# STM32H5E4xx register map
File version: 1.0
Registers are 32-bit, read-write, reset 0x0 unless marked. A register's access mark holds for its fields unless they carry their own. Offsets are from the block's base; [hi:lo] are bit positions; lines under a group give offsets from that group; {n}, {i} and the like mark numbered series.

## ADC1 — ADC
Base 0x42028000
Same registers: ADC2 0x42028100, ADC1_S 0x52028000, ADC2_S 0x52028100
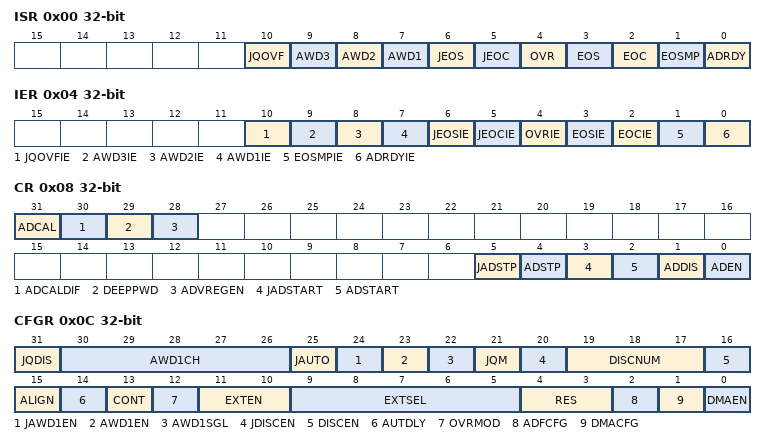
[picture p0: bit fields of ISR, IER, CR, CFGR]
0x00 ISR — ADC interrupt and status register
  [10] JQOVF — ADC group injected contexts queue overflow flag
  [9] AWD3 — ADC analog watchdog 3 flag
  [8] AWD2 — ADC analog watchdog 2 flag
  [7] AWD1 — ADC analog watchdog 1 flag
  [6] JEOS — ADC group injected end of sequence conversions flag
  [5] JEOC — ADC group injected end of unitary conversion flag
  [4] OVR — ADC group regular overrun flag
  [3] EOS — ADC group regular end of sequence conversions flag
  [2] EOC — ADC group regular end of unitary conversion flag
  [1] EOSMP — ADC group regular end of sampling flag
  [0] ADRDY — ADC ready flag
0x04 IER — ADC interrupt enable register
  [10] JQOVFIE — ADC group injected contexts queue overflow interrupt
  [9] AWD3IE — ADC analog watchdog 3 interrupt
  [8] AWD2IE — ADC analog watchdog 2 interrupt
  [7] AWD1IE — ADC analog watchdog 1 interrupt
  [6] JEOSIE — ADC group injected end of sequence conversions interrupt
  [5] JEOCIE — ADC group injected end of unitary conversion interrupt
  [4] OVRIE — ADC group regular overrun interrupt
  [3] EOSIE — ADC group regular end of sequence conversions interrupt
  [2] EOCIE — ADC group regular end of unitary conversion interrupt
  [1] EOSMPIE — ADC group regular end of sampling interrupt
  [0] ADRDYIE — ADC ready interrupt
0x08 CR — ADC control register
  [31] ADCAL — ADC calibration
  [30] ADCALDIF — ADC differential mode for calibration
  [29] DEEPPWD — ADC deep power down enable
  [28] ADVREGEN — ADC voltage regulator enable
  [5] JADSTP — ADC group injected conversion stop
  [4] ADSTP — ADC group regular conversion stop
  [3] JADSTART — ADC group injected conversion start
  [2] ADSTART — ADC group regular conversion start
  [1] ADDIS — ADC disable
  [0] ADEN — ADC enable
0x0C CFGR — ADC configuration register 1
  [31] JQDIS — ADC group injected contexts queue disable
  [30:26] AWD1CH — ADC analog watchdog 1 monitored channel selection
  [25] JAUTO — ADC group injected automatic trigger mode
    0=INDEPENDENT; 1=FROM_GRP_REGULAR
  [24] JAWD1EN — ADC analog watchdog 1 enable on scope ADC group injected
  [23] AWD1EN — ADC analog watchdog 1 enable on scope ADC group regular
  [22] AWD1SGL — ADC analog watchdog 1 monitoring a single channel or all channels
  [21] JQM — ADC group injected contexts queue mode
  [20] JDISCEN — ADC group injected sequencer discontinuous mode
    0=DISABLE; 1=DISCONT_1RANK
  [19:17] DISCNUM — ADC group regular sequencer discontinuous number of ranks
  [16] DISCEN — ADC group regular sequencer discontinuous mode
  [15] ALIGN — ADC data alignment
    0=RIGHT; 1=LEFT
  [14] AUTDLY — ADC low power auto wait
    0=MODE_NONE (No ADC low power mode activated); 1=AUTOWAIT
  [13] CONT — ADC group regular continuous conversion mode
    0=SINGLE; 1=CONTINUOUS
  [12] OVRMOD — ADC group regular overrun configuration
    0=PRESERVED; 1=OVERWRITTEN
  [11:10] EXTEN — ADC group regular external trigger polarity
    1=RISING; 2=FALLING; 3=RISINGFALLING
  [9:5] EXTSEL — ADC group regular external trigger source
  [4:3] RES — ADC data resolution
    0=RESOLUTION_12B (ADC resolution 12 bits); 1=RESOLUTION_10B (ADC resolution 10 bits); 2=RESOLUTION_8B (ADC resolution 8 bits); 3=RESOLUTION_6B (ADC resolution 6 bits)
  [2] ADFCFG — ADC ADF mode configuration
    0=NONE; 1=ENABLE
  [1] DMACFG — ADC DMA transfer configuration
  [0] DMAEN — ADC DMA transfer enable
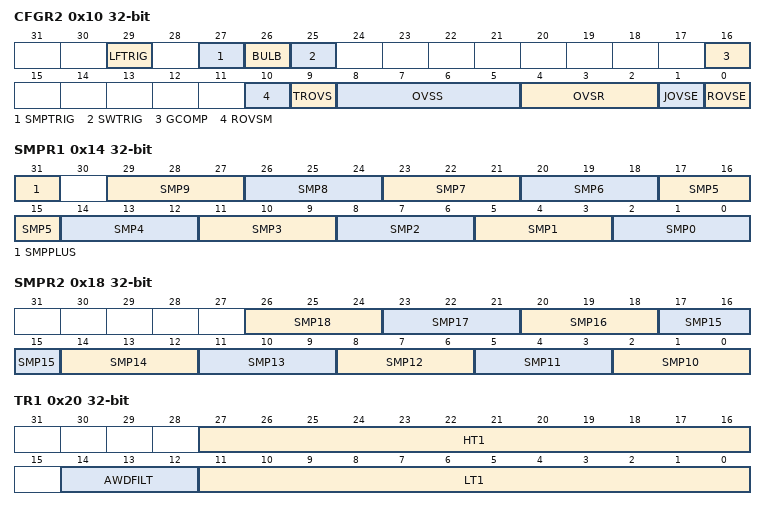
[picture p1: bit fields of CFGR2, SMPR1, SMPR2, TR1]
0x10 CFGR2 — ADC configuration register 2
  [29] LFTRIG — ADC Low Frequency Trigger
  [27] SMPTRIG — ADC Sample Time Control Trigger mode
  [26] BULB — ADC Bulb sampling mode
  [25] SWTRIG — ADC Software Trigger Bit for Sample time control trigger mode
  [16] GCOMP — ADC Gain Compensation mode
  [10] ROVSM — ADC oversampling mode managing interlaced conversions of ADC group regular and group injected
  [9] TROVS — ADC oversampling discontinuous mode (triggered mode) for ADC group regular
    0=CONT; 1=DISCONT
  [8:5] OVSS — ADC oversampling shift
    0=NONE; {v}=RIGHT_{v} (v=1..8)
  [4:2] OVSR — ADC oversampling ratio
    0=RATIO_2; 1=RATIO_4; 2=RATIO_8; 3=RATIO_16; 4=RATIO_32; 5=RATIO_64; 6=RATIO_128; 7=RATIO_256
  [1] JOVSE — ADC oversampler enable on scope ADC group injected
  [0] ROVSE — ADC oversampler enable on scope ADC group regular
0x14 SMPR1 — ADC sampling time register 1
  [31] SMPPLUS — ADC channels sampling time additional setting
    0=DEFAULT (ADC sampling time let to default settings.); 1=COMMON_3C5_REPL_2C5
  [3n+2:3n] SMP{n} (n=0..9) — ADC channel {n} sampling time selection
0x18 SMPR2 — ADC sampling time register 2
  [3n-28:3n-30] SMP{n} (n=10..18) — ADC channel {n} sampling time selection
0x20 TR1 — ADC analog watchdog 1 threshold register
  [27:16] HT1 — ADC analog watchdog 1 threshold high
  [14:12] AWDFILT — ADC analog watchdog filtering parameter
  [11:0] LT1 — ADC analog watchdog 1 threshold low
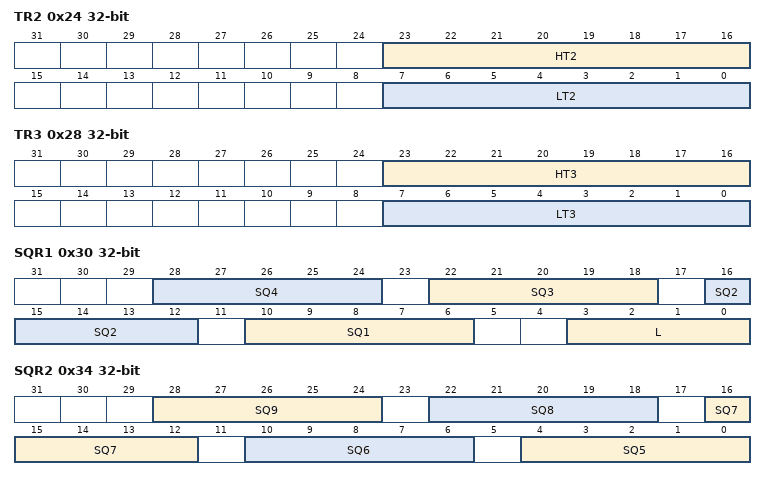
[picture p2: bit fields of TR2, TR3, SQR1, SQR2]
0x24 TR2 — ADC analog watchdog 2 threshold register
  [23:16] HT2 — ADC analog watchdog 2 threshold high
  [7:0] LT2 — ADC analog watchdog 2 threshold low
0x28 TR3 — ADC analog watchdog 3 threshold register
  [23:16] HT3 — ADC analog watchdog 3 threshold high
  [7:0] LT3 — ADC analog watchdog 3 threshold low
0x30 SQR1 — ADC group regular sequencer register 1
  [6n+4:6n] SQ{n} (n=1..4) — ADC group regular sequencer rank {n}
  [3:0] L — ADC group regular sequencer scan length
    0=DISABLE; {v}=ENABLE_{v+1}RANKS (v=1..15)
0x34 SQR2 — ADC group regular sequencer register 2
  [6n-26:6n-30] SQ{n} (n=5..9) — ADC group regular sequencer rank {n}
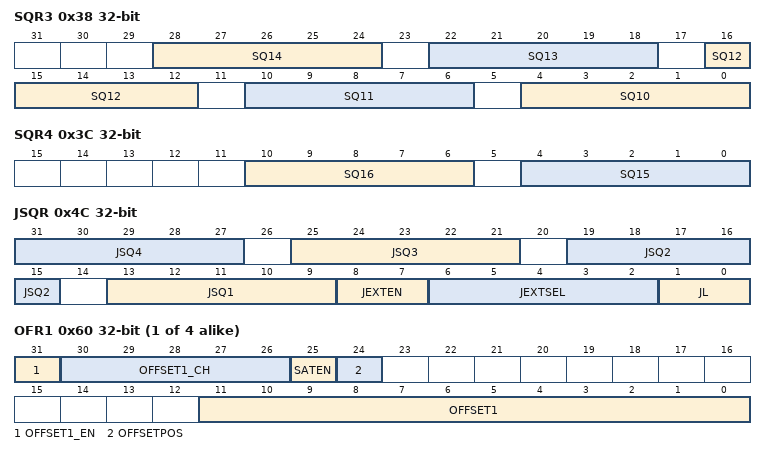
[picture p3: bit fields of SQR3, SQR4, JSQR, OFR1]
0x38 SQR3 — ADC group regular sequencer register 3
  [6n-56:6n-60] SQ{n} (n=10..14) — ADC group regular sequencer rank {n}
0x3C SQR4 — ADC group regular sequencer register 4
  [10:6] SQ16 — ADC group regular sequencer rank 16
  [4:0] SQ15 — ADC group regular sequencer rank 15
0x40 DR — ADC group regular data register
  [15:0] RDATA — ADC group regular conversion data
0x4C JSQR — ADC group injected sequencer register
  [6n+7:6n+3] JSQ{n} (n=1..4) — ADC group injected sequencer rank {n}
  [8:7] JEXTEN — ADC group injected external trigger polarity
    1=RISING; 2=FALLING; 3=RISINGFALLING
  [6:2] JEXTSEL — ADC group injected external trigger source
  [1:0] JL — ADC group injected sequencer scan length
    0=DISABLE; 1=ENABLE_2RANKS; 2=ENABLE_3RANKS; 3=ENABLE_4RANKS
{0x5C+4i} OFR{i} (i=1..4) — ADC
  [31] OFFSET{i}_EN — ADC offset number {i} enable
  [30:26] OFFSET{i}_CH — ADC offset number {i} channel selection
  [25] SATEN — ADC offset number {i} saturation enable
  [24] OFFSETPOS — ADC offset number {i} positive
  [11:0] OFFSET{i} — ADC offset number {i} offset level
{0x7C+4i} JDR{i} (i=1..4) — ADC group injected rank {i} data register
  [15:0] JDATA — ADC group injected sequencer rank {i} conversion data
0xA0 AWD2CR — ADC analog watchdog 2 configuration register
  [19:0] AWD2CH — ADC analog watchdog 2 monitored channel selection
0xA4 AWD3CR — ADC analog watchdog 3 Configuration Register
  [19:0] AWD3CH — ADC analog watchdog 3 monitored channel selection
0xB0 DIFSEL — ADC differential mode selection register
  [19:0] DIFSEL — ADC channel differential or single-ended mode
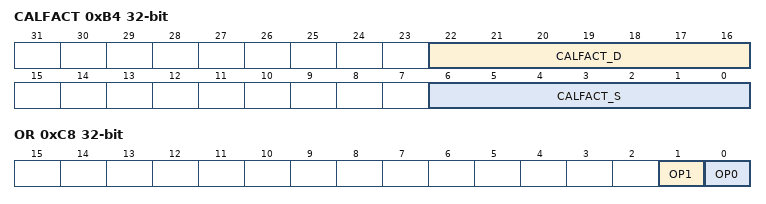
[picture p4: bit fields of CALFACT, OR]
0xB4 CALFACT — ADC calibration factors
  [22:16] CALFACT_D — ADC calibration factor in differential mode
  [6:0] CALFACT_S — ADC calibration factor in single-ended mode
0xC8 OR — ADC option register
  [1] OP1 — ADC Option bit 1
  [0] OP0 — ADC Option bit 0

## ADC3 — ADC
Base 0x4202D800
Same registers: ADC3_S 0x5202D800
Registers as ADC1; these are added or differ:
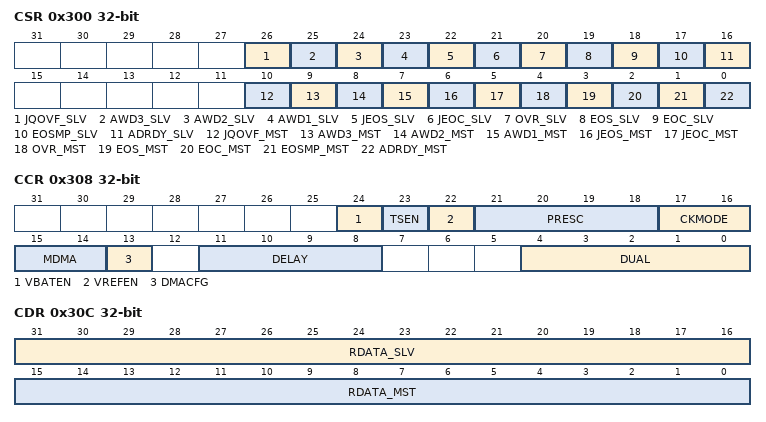
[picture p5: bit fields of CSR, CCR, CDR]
0x300 CSR — ADC common status register
  [26] JQOVF_SLV — ADC multimode slave group injected contexts queue overflow flag
  [25] AWD3_SLV — ADC multimode slave analog watchdog 3 flag
  [24] AWD2_SLV — ADC multimode slave analog watchdog 2 flag
  [23] AWD1_SLV — ADC multimode slave analog watchdog 1 flag
  [22] JEOS_SLV — ADC multimode slave group injected end of sequence conversions flag
  [21] JEOC_SLV — ADC multimode slave group injected end of unitary conversion flag
  [20] OVR_SLV — ADC multimode slave group regular overrun flag
  [19] EOS_SLV — ADC multimode slave group regular end of sequence conversions flag
  [18] EOC_SLV — ADC multimode slave group regular end of unitary conversion flag
  [17] EOSMP_SLV — ADC multimode slave group regular end of sampling flag
  [16] ADRDY_SLV — ADC multimode slave ready flag
  [10] JQOVF_MST — ADC multimode master group injected contexts queue overflow flag
  [9] AWD3_MST — ADC multimode master analog watchdog 3 flag
  [8] AWD2_MST — ADC multimode master analog watchdog 2 flag
  [7] AWD1_MST — ADC multimode master analog watchdog 1 flag
  [6] JEOS_MST — ADC multimode master group injected end of sequence conversions flag
  [5] JEOC_MST — ADC multimode master group injected end of unitary conversion flag
  [4] OVR_MST — ADC multimode master group regular overrun flag
  [3] EOS_MST — ADC multimode master group regular end of sequence conversions flag
  [2] EOC_MST — ADC multimode master group regular end of unitary conversion flag
  [1] EOSMP_MST — ADC multimode master group regular end of sampling flag
  [0] ADRDY_MST — ADC multimode master ready flag
0x308 CCR — ADC common configuration register
  [24] VBATEN — ADC internal path to battery voltage enable
  [23] TSEN — ADC internal path to temperature sensor enable
  [22] VREFEN — ADC internal path to VrefInt enable
  [21:18] PRESC — ADC common clock prescaler, only for clock source asynchronous
  [17:16] CKMODE — ADC common clock source and prescaler (prescaler only for clock source synchronous)
  [15:14] MDMA — ADC multimode DMA transfer enable
  [13] DMACFG — ADC multimode DMA transfer configuration
  [11:8] DELAY — ADC multimode delay between 2 sampling phases
    0=DELAY_1CYCLE; {v}=DELAY_{v+1}CYCLES (v=1..11)
  [4:0] DUAL — ADC multimode mode selection
    0=INDEPENDENT; 6=DUAL_REG_SIMULT; 7=DUAL_REG_INTERL; 5=DUAL_INJ_SIMULT; 9=DUAL_INJ_ALTERN; 1=DUAL_REG_SIM_INJ_SIM; 2=DUAL_REG_SIM_INJ_ALT; 3=DUAL_REG_INT_INJ_SIM
0x30C CDR — ADC common group regular data register
  [31:16] RDATA_SLV — ADC multimode slave group regular conversion data
  [15:0] RDATA_MST — ADC multimode master group regular conversion data
